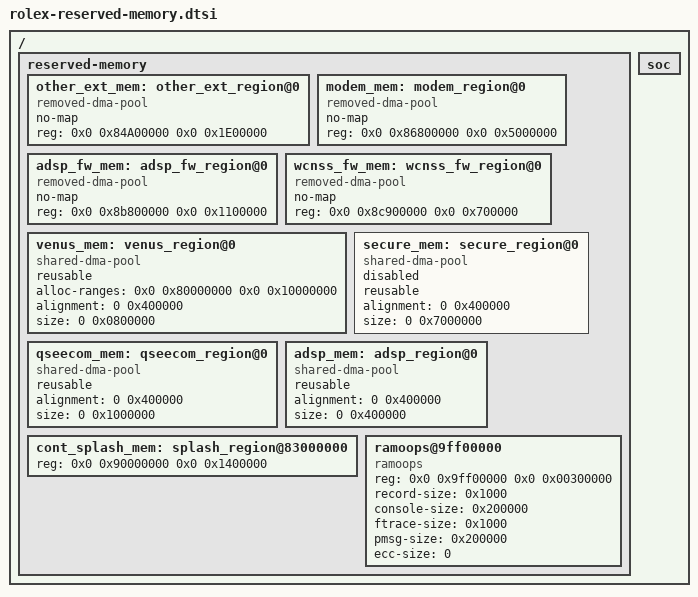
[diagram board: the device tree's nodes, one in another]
/ {
reserved-memory {
		#address-cells = <2>;
		#size-cells = <2>;
		ranges;

		other_ext_mem: other_ext_region@0 {
			compatible = "removed-dma-pool";
			no-map;
			reg = <0x0 0x84A00000 0x0 0x1E00000>;
		};

		modem_mem: modem_region@0 {
			compatible = "removed-dma-pool";
			no-map;
			reg = <0x0 0x86800000 0x0 0x5000000>;
		};

		adsp_fw_mem: adsp_fw_region@0 {
			compatible = "removed-dma-pool";
			no-map;
			reg = <0x0 0x8b800000 0x0 0x1100000>;
		};

		wcnss_fw_mem: wcnss_fw_region@0 {
			compatible = "removed-dma-pool";
			no-map;
			reg = <0x0 0x8c900000 0x0 0x700000>;
		};

		venus_mem: venus_region@0 {
			compatible = "shared-dma-pool";
			reusable;
			alloc-ranges = <0x0 0x80000000 0x0 0x10000000>;
			alignment = <0 0x400000>;
			size = <0 0x0800000>;
		};

		secure_mem: secure_region@0 {
			compatible = "shared-dma-pool";
			reusable;
			alignment = <0 0x400000>;
			size = <0 0x7000000>;
			status = "disabled";
		};

		qseecom_mem: qseecom_region@0 {
			compatible = "shared-dma-pool";
			reusable;
			alignment = <0 0x400000>;
			size = <0 0x1000000>;
		};

		adsp_mem: adsp_region@0 {
			compatible = "shared-dma-pool";
			reusable;
			alignment = <0 0x400000>;
			size = <0 0x400000>;
		};

		cont_splash_mem: splash_region@83000000 {
			reg = <0x0 0x90000000 0x0 0x1400000>;
		};

                ramoops@9ff00000 {
			compatible = "ramoops";
			reg = <0x0 0x9ff00000 0x0 0x00300000>;
			record-size = <0x1000>;
			console-size = <0x200000>;
			ftrace-size = <0x1000>;
			pmsg-size = <0x200000>;
			ecc-size = <0>;
		};
	};
	soc: soc { };
};
